AUTOSAR XML (schema 00050)
package /ComponentTypes
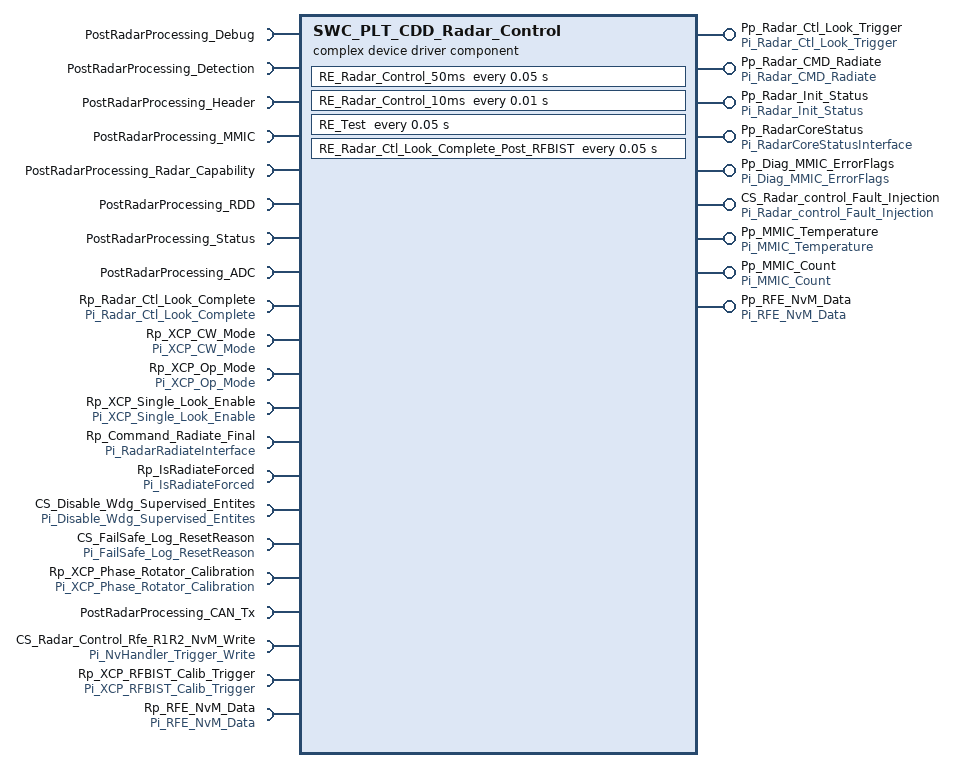
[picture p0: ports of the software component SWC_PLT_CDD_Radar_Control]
  complex device driver sw component type SWC_PLT_CDD_Radar_Control
    8 x require port:
      PostRadarProcessing_Debug: client-com-spec=Populate_Debug_Stream, required-interface=PostRadarProcessing_Debug
      PostRadarProcessing_Detection: client-com-spec=Populate_Detection_Stream, required-interface=PostRadarProcessing_Detection
      PostRadarProcessing_Header: client-com-spec=Populate_Header_Stream, required-interface=PostRadarProcessing_Header
      PostRadarProcessing_MMIC: client-com-spec=Populate_MMIC_Stream, required-interface=PostRadarProcessing_MMIC
      PostRadarProcessing_Radar_Capability: client-com-spec=Populate_Radar_Capability_Stream, required-interface=PostRadarProcessing_Radar_Capability
      PostRadarProcessing_RDD: client-com-spec=Populate_RDD_Stream, required-interface=PostRadarProcessing_RDD
      PostRadarProcessing_Status: client-com-spec=Populate_Status_Stream, required-interface=PostRadarProcessing_Status
      PostRadarProcessing_ADC: client-com-spec=Populate_ADC_Stream, required-interface=PostRadarProcessing_ADC
    provide port Pp_Radar_Ctl_Look_Trigger: server-com-spec{operation=Operation, queue-length=1}, provided-interface=Pi_Radar_Ctl_Look_Trigger
    4 x require port:
      Rp_Radar_Ctl_Look_Complete: required-interface=Pi_Radar_Ctl_Look_Complete
      Rp_XCP_CW_Mode: nonqueued-receiver-com-spec{data-element=De_XCP_CW_Mode, filter=data-filter-type=ALWAYS, init-value=0}, required-interface=Pi_XCP_CW_Mode
      Rp_XCP_Op_Mode: nonqueued-receiver-com-spec{data-element=De_XCP_Op_Mode, filter=data-filter-type=ALWAYS, init-value=0}, required-interface=Pi_XCP_Op_Mode
      Rp_XCP_Single_Look_Enable: nonqueued-receiver-com-spec{data-element=De_XCP_Single_Look_Enable, filter=data-filter-type=ALWAYS, init-value=fields=[single_look_en:0, single_look_select:0]}, required-interface=Pi_XCP_Single_Look_Enable
    provide port Pp_Radar_CMD_Radiate: nonqueued-sender-com-spec{data-element=De_Radar_CMD_Radiate, init-value=0}, provided-interface=Pi_Radar_CMD_Radiate
    provide port Pp_Radar_Init_Status: nonqueued-sender-com-spec{data-element=De_Radar_Init_Status, init-value=0}, provided-interface=Pi_Radar_Init_Status
    provide port Pp_RadarCoreStatus: nonqueued-sender-com-spec{data-element=De_RadarCoreStatus, init-value=constant-reference=C_RadarCoreStatus_T}, provided-interface=Pi_RadarCoreStatusInterface
    require port Rp_Command_Radiate_Final: nonqueued-receiver-com-spec{data-element=De_CommandRadiate_Final, filter=data-filter-type=ALWAYS, init-value=170}, required-interface=Pi_RadarRadiateInterface
    require port Rp_IsRadiateForced: nonqueued-receiver-com-spec{data-element=De_IsRadiateForced, filter=data-filter-type=ALWAYS, init-value=constant-reference=C_IsRadiateForced_T}, required-interface=Pi_IsRadiateForced
    4 x provide port:
      Pp_Diag_MMIC_ErrorFlags: nonqueued-sender-com-spec{data-element=De_MMIC_ErrorFlags, init-value=constant-reference=C_MMIC_ErrorFlags}, provided-interface=Pi_Diag_MMIC_ErrorFlags
      CS_Radar_control_Fault_Injection: server-com-spec{operation=Read, queue-length=1}, provided-interface=Pi_Radar_control_Fault_Injection
      Pp_MMIC_Temperature: nonqueued-sender-com-spec{data-element=De_MMIC_Temperature, init-value=constant-reference=C_Idt_Type_MMIC_Temperature}, provided-interface=Pi_MMIC_Temperature
      Pp_MMIC_Count: nonqueued-sender-com-spec{data-element=De_MMIC_Count, init-value=0}, provided-interface=Pi_MMIC_Count
    6 x require port:
      CS_Disable_Wdg_Supervised_Entites: client-com-spec=Operation, required-interface=Pi_Disable_Wdg_Supervised_Entites
      CS_FailSafe_Log_ResetReason: client-com-spec=FailSafe_Log_ResetReason, required-interface=Pi_FailSafe_Log_ResetReason
      Rp_XCP_Phase_Rotator_Calibration: nonqueued-receiver-com-spec{data-element=De_XCP_Phase_Rotator_Calibration, filter=data-filter-type=ALWAYS, init-value=0}, required-interface=Pi_XCP_Phase_Rotator_Calibration
      PostRadarProcessing_CAN_Tx: client-com-spec=RE_Communication_Tx, required-interface=PostRadarProcessing_CAN_Tx
      CS_Radar_Control_Rfe_R1R2_NvM_Write: client-com-spec=NvHandler_Trigger_Write_To_NVM, required-interface=Pi_NvHandler_Trigger_Write
      Rp_XCP_RFBIST_Calib_Trigger: nonqueued-receiver-com-spec{data-element=De_XCP_RFBIST_Calib_Trigger, filter=data-filter-type=ALWAYS, init-value=85}, required-interface=Pi_XCP_RFBIST_Calib_Trigger
    provide port Pp_RFE_NvM_Data: nonqueued-sender-com-spec{data-element=De_RFE_NvM_Data, init-value=fields=[CORE_BANK_SFT_ERR_MON:0, CORE_BANK_SFT_ERR_STATUS:0, CORE_BANK_MCU_STS_MCU_MSSG:0, FUSA_IRQ0_FLAG_R:0, FUSA_IRQ1_FLAG_R:0, FUSA_IRQ2_FLAG_R:0, Api_ret_val:0, LOGEN_BANK_CHRP_GEN_ERROR:0, LOGEN_BANK_LOGEN_ERROR:0, CPU_SYS_MCU_ERR_0:0, CPU_SYS_MCU_ERR_1:0, CPU_SYS_MCU_ERR_2:0, CPU_SYS_MCU_ERR_3:0, ASYNC_BANK_ASYNC_ERR1:0, PROF_BANK_PRF_ERR1:0, PROF_BANK_PRF_ERR2:0, RXADC_FUSAMON:0, maf_status:0]}, provided-interface=Pi_RFE_NvM_Data
    require port Rp_RFE_NvM_Data: nonqueued-receiver-com-spec{data-element=De_RFE_NvM_Data, filter=data-filter-type=ALWAYS, init-value=fields=[CORE_BANK_SFT_ERR_MON:0, CORE_BANK_SFT_ERR_STATUS:0, CORE_BANK_MCU_STS_MCU_MSSG:0, FUSA_IRQ0_FLAG_R:0, FUSA_IRQ1_FLAG_R:0, FUSA_IRQ2_FLAG_R:0, Api_ret_val:0, LOGEN_BANK_CHRP_GEN_ERROR:0, LOGEN_BANK_LOGEN_ERROR:0, CPU_SYS_MCU_ERR_0:0, CPU_SYS_MCU_ERR_1:0, CPU_SYS_MCU_ERR_2:0, CPU_SYS_MCU_ERR_3:0, ASYNC_BANK_ASYNC_ERR1:0, PROF_BANK_PRF_ERR1:0, PROF_BANK_PRF_ERR2:0, RXADC_FUSAMON:0, maf_status:0]}, required-interface=Pi_RFE_NvM_Data
    behavior SWC_PLT_CDD_Radar_Control_InternalBehavior: handle-termination-and-restart=NO-SUPPORT
      init event RE_Radar_Control_InitEvent: start-on-event=RE_Radar_Control_Init
      timing event TMT_RE_Radar_Control_50ms: start-on-event=RE_Radar_Control_50ms, period=0.05
      timing event TMT_RE_Radar_Control_10ms: start-on-event=RE_Radar_Control_10ms, period=0.01
      timing event TMT_RE_Test: start-on-event=RE_Test, period=0.05
      external trigger occurred event EXTO_RE_Radar_Ctl_Look_Complete_Rp_Radar_Ctl_Look_Complete_Trigger: start-on-event=RE_Radar_Ctl_Look_Complete, trigger=Rp_Radar_Ctl_Look_Complete.Trigger
      operation invoked event OIT_RE_Radar_Ctl_Look_Trigger_Pp_Radar_Ctl_Look_Trigger_Operation: start-on-event=RE_Radar_Ctl_Look_Trigger, operation=Pp_Radar_Ctl_Look_Trigger.Operation
      operation invoked event OIT_CS_Radar_control_Fault_Injection_Read_CS_Radar_control_Fault_Injection_Read: start-on-event=CS_Radar_control_Fault_Injection_Read, operation=CS_Radar_control_Fault_Injection.Read
      timing event TMT_RE_Radar_Ctl_Look_Complete_Post_RFBIST: start-on-event=RE_Radar_Ctl_Look_Complete_Post_RFBIST, offset=0.005, period=0.05
      8 x runnable:
        RE_Radar_Control_Init
          data-receive-point-by-arguments:
            access REC_Rp_RFE_NvM_Data_De_RFE_NvM_Data: accessed-variable=Rp_RFE_NvM_Data.De_RFE_NvM_Data
        RE_Radar_Control_50ms
          data-receive-point-by-arguments:
            4 x access:
              REC_Rp_XCP_CW_Mode_De_XCP_CW_Mode: accessed-variable=Rp_XCP_CW_Mode.De_XCP_CW_Mode
              REC_Rp_XCP_Op_Mode_De_XCP_Op_Mode: accessed-variable=Rp_XCP_Op_Mode.De_XCP_Op_Mode
              REC_Rp_XCP_Single_Look_Enable_De_XCP_Single_Look_Enable: accessed-variable=Rp_XCP_Single_Look_Enable.De_XCP_Single_Look_Enable
              REC_Rp_XCP_Phase_Rotator_Calibration_De_XCP_Phase_Rotator_Calibration: accessed-variable=Rp_XCP_Phase_Rotator_Calibration.De_XCP_Phase_Rotator_Calibration
          data-send-points:
            access SEND_Pp_RFE_NvM_Data_De_RFE_NvM_Data: accessed-variable=Pp_RFE_NvM_Data.De_RFE_NvM_Data
          sync call SC_CS_FailSafe_Log_ResetReason_FailSafe_Log_ResetReason: operation=CS_FailSafe_Log_ResetReason.FailSafe_Log_ResetReason
          sync call SC_CS_Disable_Wdg_Supervised_Entites_Operation: operation=CS_Disable_Wdg_Supervised_Entites.Operation
        RE_Radar_Control_10ms
        RE_Test
          9 x async call:
            AC_PostRadarProcessing_Debug_Populate_Debug_Stream: operation=PostRadarProcessing_Debug.Populate_Debug_Stream
            AC_PostRadarProcessing_Detection_Populate_Detection_Stream: operation=PostRadarProcessing_Detection.Populate_Detection_Stream
            AC_PostRadarProcessing_MMIC_Populate_MMIC_Stream: operation=PostRadarProcessing_MMIC.Populate_MMIC_Stream
            AC_PostRadarProcessing_RDD_Populate_RDD_Stream: operation=PostRadarProcessing_RDD.Populate_RDD_Stream
            AC_PostRadarProcessing_Radar_Capability_Populate_Radar_Capability_Stream: operation=PostRadarProcessing_Radar_Capability.Populate_Radar_Capability_Stream
            AC_PostRadarProcessing_Status_Populate_Status_Stream: operation=PostRadarProcessing_Status.Populate_Status_Stream
            AC_PostRadarProcessing_ADC_Populate_ADC_Stream: operation=PostRadarProcessing_ADC.Populate_ADC_Stream
            AC_PostRadarProcessing_Header_Populate_Header_Stream: operation=PostRadarProcessing_Header.Populate_Header_Stream
            AC_PostRadarProcessing_CAN_Tx_RE_Communication: operation=PostRadarProcessing_CAN_Tx.RE_Communication_Tx
        RE_Radar_Ctl_Look_Complete
          data-receive-point-by-arguments:
            access REC_Rp_Command_Radiate_Final_De_CommandRadiate_Final: accessed-variable=Rp_Command_Radiate_Final.De_CommandRadiate_Final
            access REC_Rp_IsRadiateForced_De_IsRadiateForced: accessed-variable=Rp_IsRadiateForced.De_IsRadiateForced
          data-send-points:
            access SEND_Pp_Radar_Init_Status_De_Radar_Init_Status: accessed-variable=Pp_Radar_Init_Status.De_Radar_Init_Status
            access SEND_Pp_MMIC_Count_De_MMIC_Count: accessed-variable=Pp_MMIC_Count.De_MMIC_Count
            access SEND_Pp_MMIC_Temperature_De_MMIC_Temperature: accessed-variable=Pp_MMIC_Temperature.De_MMIC_Temperature
        RE_Radar_Ctl_Look_Trigger
          data-receive-point-by-arguments:
            access REC_Rp_XCP_RFBIST_Calib_Trigger_De_XCP_RFBIST_Calib_Trigger: accessed-variable=Rp_XCP_RFBIST_Calib_Trigger.De_XCP_RFBIST_Calib_Trigger
          data-send-points:
            4 x access:
              SEND_Pp_Diag_MMIC_ErrorFlags_De_MMIC_ErrorFlags: accessed-variable=Pp_Diag_MMIC_ErrorFlags.De_MMIC_ErrorFlags
              SEND_Pp_RadarCoreStatus_De_RadarCoreStatus: accessed-variable=Pp_RadarCoreStatus.De_RadarCoreStatus
              SEND_Pp_Radar_CMD_Radiate_De_Radar_CMD_Radiate: accessed-variable=Pp_Radar_CMD_Radiate.De_Radar_CMD_Radiate
              SEND_Pp_Radar_Init_Status_De_Radar_Init_Status: accessed-variable=Pp_Radar_Init_Status.De_Radar_Init_Status
          sync call SC_CS_Radar_Control_Rfe_R1R2_NvM_Write_NvHandler_Trigger_Write_To_NVM: operation=CS_Radar_Control_Rfe_R1R2_NvM_Write.NvHandler_Trigger_Write_To_NVM
        CS_Radar_control_Fault_Injection_Read
        RE_Radar_Ctl_Look_Complete_Post_RFBIST
  swc implementation SWC_PLT_CDD_Radar_Control_Implementation: behavior=SWC_PLT_CDD_Radar_Control_InternalBehavior
